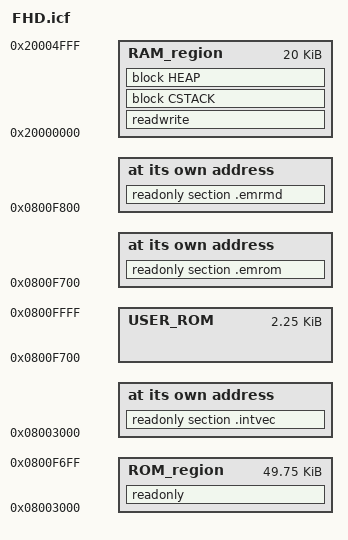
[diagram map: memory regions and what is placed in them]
/*###ICF### Section handled by ICF editor, don't touch! ****/
/*-Editor annotation file-*/
/* IcfEditorFile="$TOOLKIT_DIR$\config\ide\IcfEditor\cortex_v1_0.xml" */
/*-Specials-*/
define symbol __ICFEDIT_intvec_start__       = 0x08003000;
/*-Memory Regions-*/
define symbol __ICFEDIT_region_ROM_start__   = 0x08003000;
define symbol __ICFEDIT_region_ROM_end__     = 0x0800F6FF;

define symbol USER_ROM_START                 = 0x0800F700; 
define symbol USER_ROM_END                   = 0x0800FFFF; 

define symbol USER_MEM_START                 = 0x0800F800; 

define symbol __ICFEDIT_region_RAM_start__   = 0x20000000;
define symbol __ICFEDIT_region_RAM_end__     = 0x20004FFF;
/*-Sizes-*/
define symbol __ICFEDIT_size_cstack__        = 0x400;
define symbol __ICFEDIT_size_heap__          = 0x800;
/**** End of ICF editor section. ###ICF###*/


define memory mem with size = 4G;
define region ROM_region   = mem:[from __ICFEDIT_region_ROM_start__   to __ICFEDIT_region_ROM_end__];
define region USER_ROM     = mem:[from USER_ROM_START   to USER_ROM_END];
define region RAM_region   = mem:[from __ICFEDIT_region_RAM_start__   to __ICFEDIT_region_RAM_end__];

define block CSTACK    with alignment = 8, size = __ICFEDIT_size_cstack__   { };
define block HEAP      with alignment = 8, size = __ICFEDIT_size_heap__     { };

initialize by copy { readwrite };
do not initialize  { section .noinit };

place at address mem:__ICFEDIT_intvec_start__ { readonly section .intvec };
place at address mem:USER_ROM_START { readonly section .emrom };
place at address mem:USER_MEM_START { readonly section .emrmd };

place in ROM_region   { readonly };
place in RAM_region   { readwrite,
                        block CSTACK, block HEAP };
